VERSION ""

NS_ :

BS_:

BU_: Sensor_2 Sensor_1 TPMS_ECU

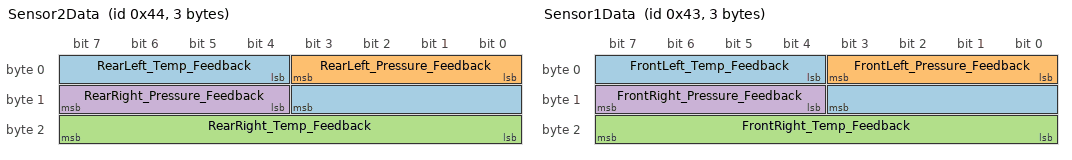
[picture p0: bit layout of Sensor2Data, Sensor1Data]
BO_ 68 Sensor2Data: 3 Sensor_2
 SG_ RearLeft_Temp_Feedback : 4|8@1+ (1,0) [0|255] "F" Vector__XXX
 SG_ RearLeft_Pressure_Feedback : 0|4@1+ (1,25) [25|40] "psi" Vector__XXX
 SG_ RearRight_Temp_Feedback : 16|8@1+ (1,0) [0|255] "F" Vector__XXX
 SG_ RearRight_Pressure_Feedback : 12|4@1+ (1,25) [25|40] "psi" Vector__XXX

BO_ 67 Sensor1Data: 3 Sensor_1
 SG_ FrontLeft_Temp_Feedback : 4|8@1+ (1,0) [0|255] "F" Vector__XXX
 SG_ FrontLeft_Pressure_Feedback : 0|4@1+ (1,25) [25|40] "psi" Vector__XXX
 SG_ FrontRight_Temp_Feedback : 16|8@1+ (1,0) [0|255] "F" Vector__XXX
 SG_ FrontRight_Pressure_Feedback : 12|4@1+ (1,25) [25|40] "psi" Vector__XXX

EV_ Ignition_Status: 0 [0|1] "" 0 1 DUMMY_NODE_VECTOR0 Vector__XXX;

BA_DEF_  "BusType" STRING ;
BA_DEF_DEF_  "BusType" "CAN";
